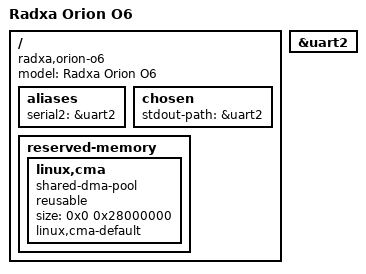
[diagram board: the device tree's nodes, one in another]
// SPDX-License-Identifier: BSD-3-Clause
/*
 * Copyright 2025 Cix Technology Group Co., Ltd.
 *
 */

/dts-v1/;

#include "sky1.dtsi"
/ {
	model = "Radxa Orion O6";
	compatible = "radxa,orion-o6", "cix,sky1";

	aliases {
		serial2 = &uart2;
	};

	chosen {
		stdout-path = &uart2;
	};

	reserved-memory {
		#address-cells = <2>;
		#size-cells = <2>;
		ranges;

		linux,cma {
			compatible = "shared-dma-pool";
			reusable;
			size = <0x0 0x28000000>;
			linux,cma-default;
		};
	};

};

&uart2 {
	status = "okay";
};
